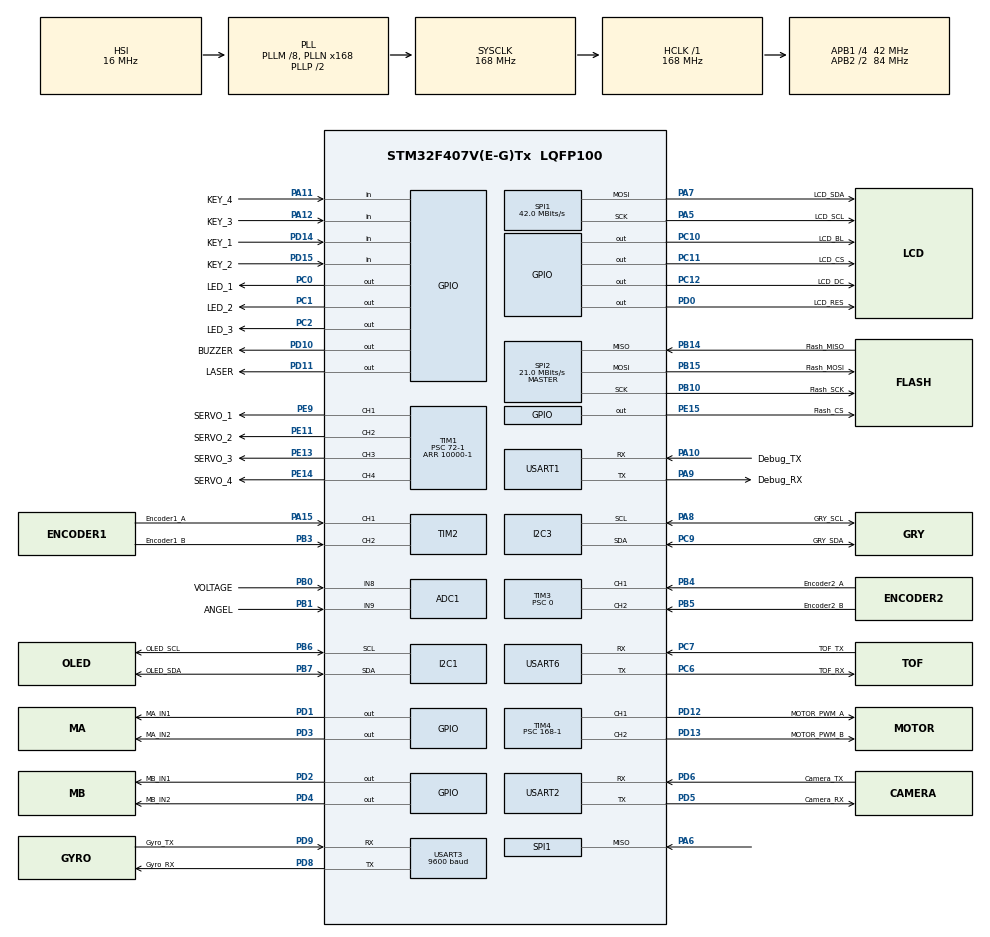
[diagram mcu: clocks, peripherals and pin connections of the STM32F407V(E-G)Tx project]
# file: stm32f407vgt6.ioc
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ADC1.Channel-0\#ChannelRegularConversion=ADC_CHANNEL_8
ADC1.NbrOfConversionFlag=1
ADC1.Rank-0\#ChannelRegularConversion=1
ADC1.SamplingTime-0\#ChannelRegularConversion=ADC_SAMPLETIME_3CYCLES
ADC1.master=1
Dma.Request0=USART6_RX
Dma.Request1=USART6_TX
Dma.Request2=USART1_TX
Dma.USART1_TX.2.Direction=DMA_MEMORY_TO_PERIPH
Dma.USART1_TX.2.FIFOMode=DMA_FIFOMODE_ENABLE
Dma.USART1_TX.2.FIFOThreshold=DMA_FIFO_THRESHOLD_FULL
Dma.USART1_TX.2.Instance=DMA2_Stream7
Dma.USART1_TX.2.MemBurst=DMA_MBURST_SINGLE
Dma.USART1_TX.2.MemDataAlignment=DMA_MDATAALIGN_BYTE
Dma.USART1_TX.2.MemInc=DMA_MINC_ENABLE
Dma.USART1_TX.2.Mode=DMA_NORMAL
Dma.USART1_TX.2.PeriphBurst=DMA_PBURST_SINGLE
Dma.USART1_TX.2.PeriphDataAlignment=DMA_PDATAALIGN_BYTE
Dma.USART1_TX.2.PeriphInc=DMA_PINC_DISABLE
Dma.USART1_TX.2.Priority=DMA_PRIORITY_LOW
Dma.USART6_RX.0.Direction=DMA_PERIPH_TO_MEMORY
Dma.USART6_RX.0.FIFOMode=DMA_FIFOMODE_ENABLE
Dma.USART6_RX.0.FIFOThreshold=DMA_FIFO_THRESHOLD_FULL
Dma.USART6_RX.0.Instance=DMA2_Stream1
Dma.USART6_RX.0.MemBurst=DMA_MBURST_SINGLE
Dma.USART6_RX.0.MemDataAlignment=DMA_MDATAALIGN_BYTE
Dma.USART6_RX.0.MemInc=DMA_MINC_ENABLE
Dma.USART6_RX.0.Mode=DMA_NORMAL
Dma.USART6_RX.0.PeriphBurst=DMA_PBURST_SINGLE
Dma.USART6_RX.0.PeriphDataAlignment=DMA_PDATAALIGN_BYTE
Dma.USART6_RX.0.PeriphInc=DMA_PINC_DISABLE
Dma.USART6_RX.0.Priority=DMA_PRIORITY_LOW
Dma.USART6_TX.1.Direction=DMA_MEMORY_TO_PERIPH
Dma.USART6_TX.1.FIFOMode=DMA_FIFOMODE_DISABLE
Dma.USART6_TX.1.Instance=DMA2_Stream6
Dma.USART6_TX.1.MemDataAlignment=DMA_MDATAALIGN_BYTE
Dma.USART6_TX.1.MemInc=DMA_MINC_ENABLE
Dma.USART6_TX.1.Mode=DMA_NORMAL
Dma.USART6_TX.1.PeriphDataAlignment=DMA_PDATAALIGN_BYTE
Dma.USART6_TX.1.PeriphInc=DMA_PINC_DISABLE
Dma.USART6_TX.1.Priority=DMA_PRIORITY_LOW
Mcu.Family=STM32F4
Mcu.Name=STM32F407V(E-G)Tx
Mcu.Package=LQFP100
NVIC.DMA2_Stream1_IRQn=true\:0\:0\:false\:false\:true\:false\:true\:true
NVIC.DMA2_Stream6_IRQn=true\:0\:0\:false\:false\:true\:false\:true\:true
NVIC.DMA2_Stream7_IRQn=true\:0\:0\:false\:false\:true\:false\:true\:true
NVIC.PriorityGroup=NVIC_PRIORITYGROUP_4
NVIC.TIM1_BRK_TIM9_IRQn=true\:0\:0\:false\:false\:true\:true\:true\:true
NVIC.TIM5_IRQn=true\:0\:0\:false\:false\:true\:true\:true\:true
NVIC.TIM8_UP_TIM13_IRQn=true\:15\:0\:false\:false\:true\:false\:true\:true
NVIC.TimeBase=TIM8_UP_TIM13_IRQn
NVIC.TimeBaseIP=TIM8
NVIC.USART1_IRQn=true\:0\:0\:false\:false\:true\:true\:true\:true
NVIC.USART3_IRQn=true\:0\:0\:false\:false\:true\:true\:true\:true
NVIC.USART6_IRQn=true\:0\:0\:false\:false\:true\:true\:true\:true
PA10.GPIO_Label=Debug_TX
PA10.Mode=Asynchronous
PA10.Signal=USART1_RX
PA11.GPIO_Label=KEY_4
PA11.GPIO_PuPd=GPIO_PULLUP
PA11.Signal=GPIO_Input
PA12.GPIO_Label=KEY_3
PA12.GPIO_PuPd=GPIO_PULLUP
PA12.Signal=GPIO_Input
PA13.Mode=Serial_Wire
PA13.Signal=SYS_JTMS-SWDIO
PA14.Mode=Serial_Wire
PA14.Signal=SYS_JTCK-SWCLK
PA15.GPIO_Label=Encoder1_A
PA15.Signal=S_TIM2_CH1_ETR
PA5.GPIO_Label=LCD_SCL
PA5.Mode=Full_Duplex_Master
PA5.Signal=SPI1_SCK
PA6.Mode=Full_Duplex_Master
PA6.Signal=SPI1_MISO
PA7.GPIO_Label=LCD_SDA
PA7.Mode=Full_Duplex_Master
PA7.Signal=SPI1_MOSI
PA8.GPIO_Label=GRY_SCL
PA8.Mode=I2C
PA8.Signal=I2C3_SCL
PA9.GPIO_Label=Debug_RX
PA9.Mode=Asynchronous
PA9.Signal=USART1_TX
PB0.GPIO_Label=VOLTAGE
PB0.Signal=ADCx_IN8
PB1.GPIO_Label=ANGEL
PB1.Signal=ADCx_IN9
PB10.GPIO_Label=Flash_SCK
PB10.Mode=Full_Duplex_Master
PB10.Signal=SPI2_SCK
PB14.GPIO_Label=Flash_MISO
PB14.Mode=Full_Duplex_Master
PB14.Signal=SPI2_MISO
PB15.GPIO_Label=Flash_MOSI
PB15.Mode=Full_Duplex_Master
PB15.Signal=SPI2_MOSI
PB3.GPIO_Label=Encoder1_B
PB3.Signal=S_TIM2_CH2
PB4.GPIO_Label=Encoder2_A
PB4.Signal=S_TIM3_CH1
PB5.GPIO_Label=Encoder2_B
PB5.Signal=S_TIM3_CH2
PB6.GPIO_Label=OLED_SCL
PB6.Mode=I2C
PB6.Signal=I2C1_SCL
PB7.GPIO_Label=OLED_SDA
PB7.Mode=I2C
PB7.Signal=I2C1_SDA
PC0.GPIO_Label=LED_1
PC0.GPIO_PuPd=GPIO_PULLUP
PC0.Signal=GPIO_Output
PC1.GPIO_Label=LED_2
PC1.GPIO_PuPd=GPIO_PULLUP
PC1.Signal=GPIO_Output
PC10.GPIO_Label=LCD_BL
PC10.Signal=GPIO_Output
PC11.GPIO_Label=LCD_CS
PC11.Signal=GPIO_Output
PC12.GPIO_Label=LCD_DC
PC12.Signal=GPIO_Output
PC14-OSC32_IN.Mode=LSE-External-Oscillator
PC14-OSC32_IN.Signal=RCC_OSC32_IN
PC15-OSC32_OUT.Mode=LSE-External-Oscillator
PC15-OSC32_OUT.Signal=RCC_OSC32_OUT
PC2.GPIO_Label=LED_3
PC2.GPIO_PuPd=GPIO_PULLUP
PC2.Signal=GPIO_Output
PC6.GPIO_Label=TOF_RX
PC6.Mode=Asynchronous
PC6.Signal=USART6_TX
PC7.GPIO_Label=TOF_TX
PC7.Mode=Asynchronous
PC7.Signal=USART6_RX
PC9.GPIO_Label=GRY_SDA
PC9.Mode=I2C
PC9.Signal=I2C3_SDA
PD0.GPIO_Label=LCD_RES
PD0.Signal=GPIO_Output
PD1.GPIO_Label=MA_IN1
PD1.Signal=GPIO_Output
PD10.GPIO_Label=BUZZER
PD10.Signal=GPIO_Output
PD11.GPIO_Label=LASER
PD11.Signal=GPIO_Output
PD12.GPIO_Label=MOTOR_PWM_A
PD12.Signal=S_TIM4_CH1
PD13.GPIO_Label=MOTOR_PWM_B
PD13.Signal=S_TIM4_CH2
PD14.GPIO_Label=KEY_1
PD14.GPIO_PuPd=GPIO_PULLUP
PD14.Signal=GPIO_Input
PD15.GPIO_Label=KEY_2
PD15.GPIO_PuPd=GPIO_PULLUP
PD15.Signal=GPIO_Input
PD2.GPIO_Label=MB_IN1
PD2.Signal=GPIO_Output
PD3.GPIO_Label=MA_IN2
PD3.Signal=GPIO_Output
PD4.GPIO_Label=MB_IN2
PD4.Signal=GPIO_Output
PD5.GPIO_Label=Camera_RX
PD5.Mode=Asynchronous
PD5.Signal=USART2_TX
PD6.GPIO_Label=Camera_TX
PD6.Mode=Asynchronous
PD6.Signal=USART2_RX
PD8.GPIO_Label=Gyro_RX
PD8.Mode=Asynchronous
PD8.Signal=USART3_TX
PD9.GPIO_Label=Gyro_TX
PD9.Mode=Asynchronous
PD9.Signal=USART3_RX
PE11.GPIO_Label=SERVO_2
PE11.Signal=S_TIM1_CH2
PE13.GPIO_Label=SERVO_3
PE13.Signal=S_TIM1_CH3
PE14.GPIO_Label=SERVO_4
PE14.Signal=S_TIM1_CH4
PE15.GPIO_Label=Flash_CS
PE15.Signal=GPIO_Output
PE9.GPIO_Label=SERVO_1
PE9.Signal=S_TIM1_CH1
PH0-OSC_IN.Mode=HSE-External-Oscillator
PH0-OSC_IN.Signal=RCC_OSC_IN
PH1-OSC_OUT.Mode=HSE-External-Oscillator
PH1-OSC_OUT.Signal=RCC_OSC_OUT
ProjectManager.HeapSize=0x200
ProjectManager.StackSize=0x400
ProjectManager.TargetToolchain=MDK-ARM V5.32
RCC.48MHZClocksFreq_Value=84000000
RCC.AHBFreq_Value=168000000
RCC.APB1CLKDivider=RCC_HCLK_DIV4
RCC.APB1Freq_Value=42000000
RCC.APB1TimFreq_Value=84000000
RCC.APB2CLKDivider=RCC_HCLK_DIV2
RCC.APB2Freq_Value=84000000
RCC.APB2TimFreq_Value=168000000
RCC.CortexFreq_Value=168000000
RCC.HCLKFreq_Value=168000000
RCC.HSE_VALUE=25000000
RCC.HSI_VALUE=16000000
RCC.PLLM=8
RCC.PLLN=168
RCC.SYSCLKFreq_VALUE=168000000
RCC.SYSCLKSource=RCC_SYSCLKSOURCE_PLLCLK
RCC.VCOOutputFreq_Value=336000000
SH.ADCx_IN8.0=ADC1_IN8,IN8
SH.ADCx_IN9.0=ADC1_IN9,IN9
SH.S_TIM1_CH1.0=TIM1_CH1,PWM Generation1 CH1
SH.S_TIM1_CH2.0=TIM1_CH2,PWM Generation2 CH2
SH.S_TIM1_CH3.0=TIM1_CH3,PWM Generation3 CH3
SH.S_TIM1_CH4.0=TIM1_CH4,PWM Generation4 CH4
SH.S_TIM2_CH1_ETR.0=TIM2_CH1,Encoder_Interface
SH.S_TIM2_CH2.0=TIM2_CH2,Encoder_Interface
SH.S_TIM3_CH1.0=TIM3_CH1,Encoder_Interface
SH.S_TIM3_CH2.0=TIM3_CH2,Encoder_Interface
SH.S_TIM4_CH1.0=TIM4_CH1,PWM Generation1 CH1
SH.S_TIM4_CH2.0=TIM4_CH2,PWM Generation2 CH2
SPI1.BaudRatePrescaler=SPI_BAUDRATEPRESCALER_2
SPI1.CalculateBaudRate=42.0 MBits/s
SPI1.Direction=SPI_DIRECTION_2LINES
SPI1.Mode=SPI_MODE_MASTER
SPI1.VirtualType=VM_MASTER
SPI2.CalculateBaudRate=21.0 MBits/s
SPI2.Direction=SPI_DIRECTION_2LINES
SPI2.Mode=SPI_MODE_MASTER
SPI2.VirtualType=VM_MASTER
TIM1.Channel-PWM\ Generation1\ CH1=TIM_CHANNEL_1
TIM1.Channel-PWM\ Generation2\ CH2=TIM_CHANNEL_2
TIM1.Channel-PWM\ Generation3\ CH3=TIM_CHANNEL_3
TIM1.Channel-PWM\ Generation4\ CH4=TIM_CHANNEL_4
TIM1.Period=10000-1
TIM1.Prescaler=72-1
TIM14.Period=499
TIM14.Prescaler=83
TIM2.EncoderMode=TIM_ENCODERMODE_TI12
TIM2.IC2Polarity=TIM_ICPOLARITY_RISING
TIM3.EncoderMode=TIM_ENCODERMODE_TI12
TIM3.IC1Polarity=TIM_ICPOLARITY_FALLING
TIM3.Prescaler=0
TIM4.Channel-PWM\ Generation1\ CH1=TIM_CHANNEL_1
TIM4.Channel-PWM\ Generation2\ CH2=TIM_CHANNEL_2
TIM4.Period=10000-1
TIM4.Prescaler=168-1
TIM5.Period=5000
TIM5.Prescaler=168-1
TIM9.Period=10000-1
TIM9.Prescaler=168-1
USART1.VirtualMode=VM_ASYNC
USART2.VirtualMode=VM_ASYNC
USART3.BaudRate=9600
USART3.VirtualMode=VM_ASYNC
USART6.VirtualMode=VM_ASYNC
VP_SYS_VS_tim8.Mode=TIM8
VP_TIM14_VS_ClockSourceINT.Mode=Enable_Timer
VP_TIM5_VS_ClockSourceINT.Mode=Internal
VP_TIM9_VS_ClockSourceINT.Mode=Internal
board=custom

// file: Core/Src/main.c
/* USER CODE BEGIN Header */
/**
  ******************************************************************************
  * @file           : main.c
  * @brief          : Main program body
  ******************************************************************************
  * @attention
  *
  * Copyright (c) 2025 STMicroelectronics.
  * All rights reserved.
  *
  * This software is licensed under terms that can be found in the LICENSE file
  * in the root directory of this software component.
  * If no LICENSE file comes with this software, it is provided AS-IS.
  *
  ******************************************************************************
  */
/* USER CODE END Header */
#include "main.h"
#include "adc.h"
#include "dma.h"
#include "i2c.h"
#include "spi.h"
#include "tim.h"
#include "usart.h"
#include "gpio.h"

/* USER CODE BEGIN Includes */
#include "app.h"
#include "bsp.h"

#if USE_TEST
    #include "test.h"
#endif

/* USER CODE END Includes */

void SystemClock_Config(void);

int main(void)
{

  /* MCU Configuration--------------------------------------------------------*/

  /* Reset of all peripherals, Initializes the Flash interface and the Systick. */
  HAL_Init();

  /* Configure the system clock */
  SystemClock_Config();

  /* Initialize all configured peripherals */
  MX_GPIO_Init();
  MX_DMA_Init();
  MX_ADC1_Init();
  MX_I2C1_Init();
  MX_I2C3_Init();
  MX_SPI1_Init();
  MX_SPI2_Init();
  MX_TIM1_Init();
  MX_TIM3_Init();
  MX_TIM4_Init();
  MX_USART1_UART_Init();
  MX_USART2_UART_Init();
  MX_USART3_UART_Init();
  MX_USART6_UART_Init();
  MX_TIM2_Init();
  MX_TIM9_Init();
  MX_TIM14_Init();
  MX_TIM5_Init();
  /* USER CODE BEGIN 2 */

#if USE_TEST
    // if use the test, then it will block.
    test_main();

#endif

    // init
    app_setup();
    // loop
    app_loop();

  /* USER CODE END 2 */

  /* Infinite loop */
  while (1)
  {

    /* USER CODE BEGIN 3 */

    /* USER CODE BEGIN 3 */
  }
  /* USER CODE END 3 */
}

void SystemClock_Config(void)
{
  RCC_OscInitTypeDef RCC_OscInitStruct = {0};
  RCC_ClkInitTypeDef RCC_ClkInitStruct = {0};

  /** Configure the main internal regulator output voltage
  */
  __HAL_RCC_PWR_CLK_ENABLE();
  __HAL_PWR_VOLTAGESCALING_CONFIG(PWR_REGULATOR_VOLTAGE_SCALE1);

  /** Initializes the RCC Oscillators according to the specified parameters
  * in the RCC_OscInitTypeDef structure.
  */
  RCC_OscInitStruct.OscillatorType = RCC_OSCILLATORTYPE_HSI;
  RCC_OscInitStruct.HSIState = RCC_HSI_ON;
  RCC_OscInitStruct.HSICalibrationValue = RCC_HSICALIBRATION_DEFAULT;
  RCC_OscInitStruct.PLL.PLLState = RCC_PLL_ON;
  RCC_OscInitStruct.PLL.PLLSource = RCC_PLLSOURCE_HSI;
  RCC_OscInitStruct.PLL.PLLM = 8;
  RCC_OscInitStruct.PLL.PLLN = 168;
  RCC_OscInitStruct.PLL.PLLP = RCC_PLLP_DIV2;
  RCC_OscInitStruct.PLL.PLLQ = 4;
  if (HAL_RCC_OscConfig(&RCC_OscInitStruct) != HAL_OK)
  {
    Error_Handler();
  }

  /** Initializes the CPU, AHB and APB buses clocks
  */
  RCC_ClkInitStruct.ClockType = RCC_CLOCKTYPE_HCLK|RCC_CLOCKTYPE_SYSCLK
                              |RCC_CLOCKTYPE_PCLK1|RCC_CLOCKTYPE_PCLK2;
  RCC_ClkInitStruct.SYSCLKSource = RCC_SYSCLKSOURCE_PLLCLK;
  RCC_ClkInitStruct.AHBCLKDivider = RCC_SYSCLK_DIV1;
  RCC_ClkInitStruct.APB1CLKDivider = RCC_HCLK_DIV4;
  RCC_ClkInitStruct.APB2CLKDivider = RCC_HCLK_DIV2;

  if (HAL_RCC_ClockConfig(&RCC_ClkInitStruct, FLASH_LATENCY_5) != HAL_OK)
  {
    Error_Handler();
  }
}

void HAL_TIM_PeriodElapsedCallback(TIM_HandleTypeDef *htim)
{
  if (htim->Instance == TIM8)
  {
    HAL_IncTick();
  }
  /* USER CODE BEGIN Callback 1 */
  // 转到自己的回调函数去，在isr.c
  extern void My_TIM_PeriodElapsedCallback(TIM_HandleTypeDef *htim);
  My_TIM_PeriodElapsedCallback(htim);

  /* USER CODE END Callback 1 */
}

void Error_Handler(void)
{
  __disable_irq();
  while (1)
  {
  }
}
